# M471 register map
File version: 1.0
Registers are 32-bit, read-write, reset 0x0 unless marked. A register's access mark holds for its fields unless they carry their own. Offsets are from the block's base; [hi:lo] are bit positions; {n}, {i} and the like mark numbered series.

## PRNG — PRNG Register Map
Base 0x400BA000
0x00 PRNG_INTEN — PRNG Interrupt Enable Control Register
  [16] PRNGIEN — PRNG Interrupt Enable Bit
    0=PRNG interrupt Disabled; 1=PRNG interrupt Enabled
0x04 PRNG_INTSTS — PRNG Interrupt Flag
  [16] PRNGIF — PRNG Finish Interrupt Flag. Note: This bit is cleared by writing 1, and it has no effect by writing 0.
    0=No PRNG interrupt; 1=PRNG key generation done interrupt
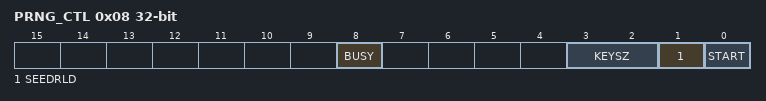
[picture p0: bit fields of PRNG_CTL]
0x08 PRNG_CTL — PRNG Control Register
  [8] BUSY ro — PRNG Busy (Read Only)
    0=PRNG engine is idle; 1=PRNG engine is generating PRNG_KEYx
  [3:2] KEYSZ — PRNG Generate Key Size
    0=64 bits; 1=128 bits; 2=192 bits; 3=256 bits
  [1] SEEDRLD — Reload New Seed for PRNG Engine
    0=Generating key based on the current seed; 1=Reload new seed
  [0] START — Start PRNG Engine
    0=Stop PRNG engine; 1=Generate a new key and store the new key to the register PRNG_KEYx, which will be cleared when the new key is generated
0x0C PRNG_SEED wo reset 0xFFFFFFFF — Seed for PRNG
  [31:0] SEED — Seed for PRNG (Write Only). The bits store the seed for PRNG engine.
{0x10+4i} PRNG_KEY{i} ro reset 0xFFFFFFFF (i=0..7) — PRNG Generated Key{i}
  [31:0] KEY — Store PRNG Generated Key (Read Only). The bits store the key that is generated by PRNG.

## DAC — DAC Register Map
Base 0x40047000
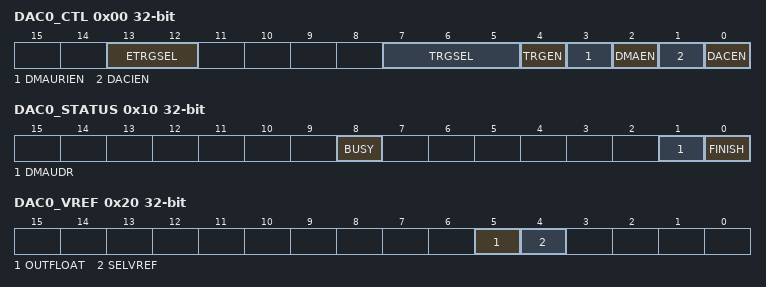
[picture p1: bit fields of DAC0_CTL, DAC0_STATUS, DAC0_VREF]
0x00 DAC0_CTL — DAC0 Control Register
  [13:12] ETRGSEL — External Pin Trigger Selection
    0=Low level trigger; 1=High level trigger; 2=Falling edge trigger; 3=Rising edge trigger
  [7:5] TRGSEL — Trigger Source Selection
    0=Software trigger; 1=External pin DAC0_ST trigger; {v}=Timer {v-2} trigger (v=2..5); 6=EPWM0 trigger; 7=EPWM1 trigger
  [4] TRGEN — Trigger Mode Enable Bit
    0=DAC event trigger mode Disabled; 1=DAC event trigger mode Enabled
  [3] DMAURIEN — DMA Under-run Interrupt Enable Bit
    0=DMA under-run interrupt Disabled; 1=DMA under-run interrupt Enabled
  [2] DMAEN — DMA Mode Enable Bit
    0=DMA mode Disabled; 1=DMA mode Enabled
  [1] DACIEN — DAC Interrupt Enable Bit
    0=DAC interrupt Disabled; 1=DAC interrupt Enabled
  [0] DACEN — DAC Enable Bit
    0=DAC Disabled; 1=DAC Enabled
0x04 DAC0_SWTRG — DAC0 Software Trigger Control Register
  [0] SWTRG — Software Trigger. Note: User writes this bit to generate one shot pulse and this bit is cleared to 0 by hardware automatically; reading this bit will always get 0.
    0=Software trigger Disabled; 1=Software trigger Enabled
0x08 DAC0_DAT — DAC0 Data Holding Register
  [7:0] DACDAT — DAC 8-bit Holding Data. These bits are written by user software which specifies 8-bit conversion data for DAC output.
0x0C DAC0_DATOUT ro — DAC0 Data Output Register
  [11:0] DATOUT — DAC 8-bit Output Data. These bits are current digital data for DAC output conversion. It is loaded from DAC_DAT register and user cannot write it directly.
0x10 DAC0_STATUS
  [8] BUSY ro — DAC Busy Flag (Read Only)
    0=DAC is ready for next conversion; 1=DAC is busy in conversion
  [1] DMAUDR — DMA Under-run Interrupt Flag. Note: User writes 1 to clear this bit.
    0=No DMA under-run error condition occurred; 1=DMA under-run error condition occurred
  [0] FINISH — DAC Conversion Complete Finish Flag. Note: This bit is set to 1 when conversion time counter counts to SETTLET. It is cleared to 0 when DAC starts a new conversion. User writes 1 to clear this bit to 0.
    0=DAC is in conversion state; 1=DAC conversion finish
0x14 DAC0_TCTL — DAC0 Timing Control Register
  [9:0] SETTLET — DAC Output Settling Time. User software needs to write appropriate value to these bits to meet DAC conversion settling time base on PCLK (APB clock) speed. For example, DAC controller clock speed is 80 MHz and DAC conversion settling time is 1 us, SETTLETvalue must be greater than 0x50.
0x20 DAC0_VREF — DAC0 Reference Voltage Control Register
  [5] OUTFLOAT — DAC Output Floating Selection
    0=DAC_OUT output DAC_ROUT; 1=DAC_OUT output Hi-z
  [4] SELVREF — DAC Reference Voltage Selection
    0=DAC reference voltage is from AVDD; 1=DAC reference voltage is from VREFP
